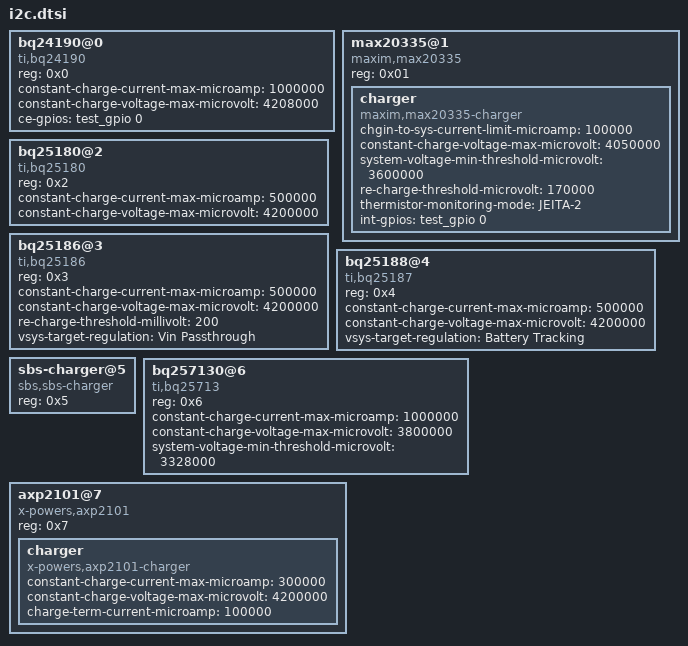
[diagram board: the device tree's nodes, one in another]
/*
 * Copyright (c) 2023 Cirrus Logic, Inc.
 * SPDX-License-Identifier: Apache-2.0
 */

/****************************************
 * PLEASE KEEP REG ADDRESSES SEQUENTIAL *
 **************************************
 */

bq24190@0 {
	compatible = "ti,bq24190";
	reg = <0x0>;
	status = "okay";

	constant-charge-current-max-microamp = <1000000>;
	constant-charge-voltage-max-microvolt = <4208000>;

	ce-gpios = <&test_gpio 0 0>;
};

max20335@1 {
	compatible = "maxim,max20335";
	reg = <0x01>;
	status = "okay";

	charger: charger {
		compatible = "maxim,max20335-charger";

		chgin-to-sys-current-limit-microamp = <100000>;
		constant-charge-voltage-max-microvolt = <4050000>;
		system-voltage-min-threshold-microvolt = <3600000>;
		re-charge-threshold-microvolt = <170000>;
		thermistor-monitoring-mode = "JEITA-2";
		int-gpios = <&test_gpio 0 0>;
	};
};

bq25180@2 {
	compatible = "ti,bq25180";
	reg = <0x2>;
	constant-charge-current-max-microamp = <500000>;
	constant-charge-voltage-max-microvolt = <4200000>;
};

bq25186@3 {
	compatible = "ti,bq25186";
	reg = <0x3>;
	constant-charge-current-max-microamp = <500000>;
	constant-charge-voltage-max-microvolt = <4200000>;
	re-charge-threshold-millivolt = <200>;
	vsys-target-regulation = "Vin Passthrough";
};

bq25188@4 {
	compatible = "ti,bq25187";
	reg = <0x4>;
	constant-charge-current-max-microamp = <500000>;
	constant-charge-voltage-max-microvolt = <4200000>;
	vsys-target-regulation = "Battery Tracking";
};

sbs-charger@5 {
	compatible = "sbs,sbs-charger";
	reg = <0x5>;
};

bq257130@6 {
	compatible = "ti,bq25713";
	reg = <0x6>;
	constant-charge-current-max-microamp = <1000000>;
	constant-charge-voltage-max-microvolt = <3800000>;
	system-voltage-min-threshold-microvolt = <3328000>;
};

axp2101@7 {
	compatible = "x-powers,axp2101";
	reg = <0x7>;

	charger {
		compatible = "x-powers,axp2101-charger";
		constant-charge-current-max-microamp = <300000>;
		constant-charge-voltage-max-microvolt = <4200000>;
		charge-term-current-microamp = <100000>;
	};
};
